# iostm32f105xx register map
Registers are 32-bit, access not given, no defined reset value unless marked. A register's access mark holds for its fields unless they carry their own. Addresses are absolute; registers are grouped by the start of their names; [hi:lo] are bit positions.

## SPI1
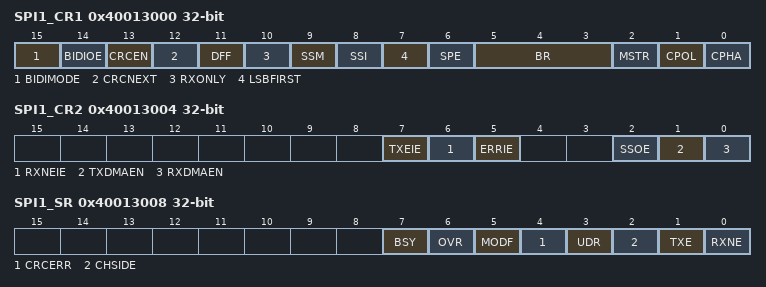
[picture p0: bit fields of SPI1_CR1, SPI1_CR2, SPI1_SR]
0x40013000 SPI1_CR1
  [15] BIDIMODE, [14] BIDIOE, [13] CRCEN, [12] CRCNEXT, [11] DFF, [10] RXONLY, [9] SSM, [8] SSI, [7] LSBFIRST, [6] SPE, [5:3] BR, [2] MSTR, [1] CPOL, [0] CPHA
0x40013004 SPI1_CR2
  [7] TXEIE, [6] RXNEIE, [5] ERRIE, [2] SSOE, [1] TXDMAEN, [0] RXDMAEN
0x40013008 SPI1_SR
  [7] BSY, [6] OVR, [5] MODF, [4] CRCERR, [3] UDR, [2] CHSIDE, [1] TXE, [0] RXNE
0x4001300C SPI1_DR
  [15:0] DR
0x40013010 SPI1_CRCPR
  [15:0] CRCPOLY
0x40013014 SPI1_RXCRCR
  [15:0] RxCRC
0x40013018 SPI1_TXCRCR
  [15:0] TxCRC

## SPI2
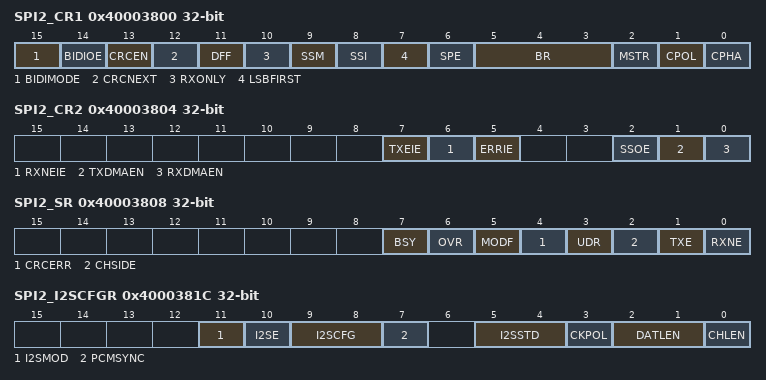
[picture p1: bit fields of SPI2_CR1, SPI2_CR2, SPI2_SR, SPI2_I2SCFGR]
0x40003800 SPI2_CR1
  [15] BIDIMODE, [14] BIDIOE, [13] CRCEN, [12] CRCNEXT, [11] DFF, [10] RXONLY, [9] SSM, [8] SSI, [7] LSBFIRST, [6] SPE, [5:3] BR, [2] MSTR, [1] CPOL, [0] CPHA
0x40003804 SPI2_CR2
  [7] TXEIE, [6] RXNEIE, [5] ERRIE, [2] SSOE, [1] TXDMAEN, [0] RXDMAEN
0x40003808 SPI2_SR
  [7] BSY, [6] OVR, [5] MODF, [4] CRCERR, [3] UDR, [2] CHSIDE, [1] TXE, [0] RXNE
0x4000380C SPI2_DR
  [15:0] DR
0x40003810 SPI2_CRCPR
  [15:0] CRCPOLY
0x40003814 SPI2_RXCRCR
  [15:0] RxCRC
0x40003818 SPI2_TXCRCR
  [15:0] TxCRC
0x4000381C SPI2_I2SCFGR
  [11] I2SMOD, [10] I2SE, [9:8] I2SCFG, [7] PCMSYNC, [5:4] I2SSTD, [3] CKPOL, [2:1] DATLEN, [0] CHLEN
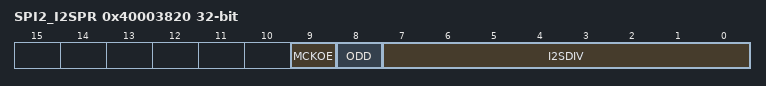
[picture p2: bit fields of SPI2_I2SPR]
0x40003820 SPI2_I2SPR
  [9] MCKOE, [8] ODD, [7:0] I2SDIV

## SPI3
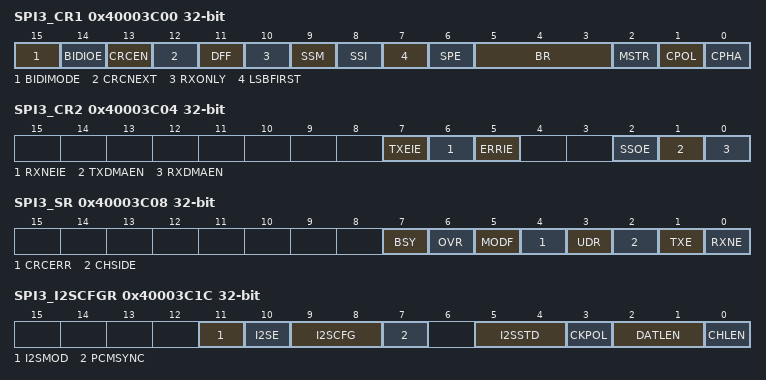
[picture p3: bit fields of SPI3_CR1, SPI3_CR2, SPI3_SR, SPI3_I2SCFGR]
0x40003C00 SPI3_CR1
  [15] BIDIMODE, [14] BIDIOE, [13] CRCEN, [12] CRCNEXT, [11] DFF, [10] RXONLY, [9] SSM, [8] SSI, [7] LSBFIRST, [6] SPE, [5:3] BR, [2] MSTR, [1] CPOL, [0] CPHA
0x40003C04 SPI3_CR2
  [7] TXEIE, [6] RXNEIE, [5] ERRIE, [2] SSOE, [1] TXDMAEN, [0] RXDMAEN
0x40003C08 SPI3_SR
  [7] BSY, [6] OVR, [5] MODF, [4] CRCERR, [3] UDR, [2] CHSIDE, [1] TXE, [0] RXNE
0x40003C0C SPI3_DR
  [15:0] DR
0x40003C10 SPI3_CRCPR
  [15:0] CRCPOLY
0x40003C14 SPI3_RXCRCR
  [15:0] RxCRC
0x40003C18 SPI3_TXCRCR
  [15:0] TxCRC
0x40003C1C SPI3_I2SCFGR
  [11] I2SMOD, [10] I2SE, [9:8] I2SCFG, [7] PCMSYNC, [5:4] I2SSTD, [3] CKPOL, [2:1] DATLEN, [0] CHLEN
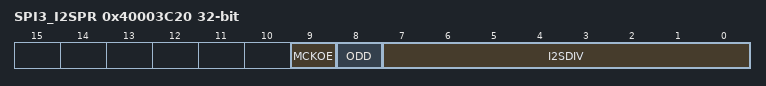
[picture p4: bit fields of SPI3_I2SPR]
0x40003C20 SPI3_I2SPR
  [9] MCKOE, [8] ODD, [7:0] I2SDIV

## USART1
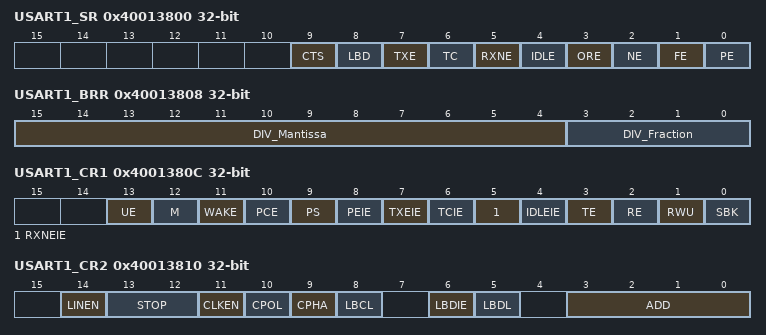
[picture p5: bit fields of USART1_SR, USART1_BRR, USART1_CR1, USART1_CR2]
0x40013800 USART1_SR
  [9] CTS, [8] LBD, [7] TXE, [6] TC, [5] RXNE, [4] IDLE, [3] ORE, [2] NE, [1] FE, [0] PE
0x40013804 USART1_DR
  [8:0] DR
0x40013808 USART1_BRR
  [15:4] DIV_Mantissa, [3:0] DIV_Fraction
0x4001380C USART1_CR1
  [13] UE, [12] M, [11] WAKE, [10] PCE, [9] PS, [8] PEIE, [7] TXEIE, [6] TCIE, [5] RXNEIE, [4] IDLEIE, [3] TE, [2] RE, [1] RWU, [0] SBK
0x40013810 USART1_CR2
  [14] LINEN, [13:12] STOP, [11] CLKEN, [10] CPOL, [9] CPHA, [8] LBCL, [6] LBDIE, [5] LBDL, [3:0] ADD
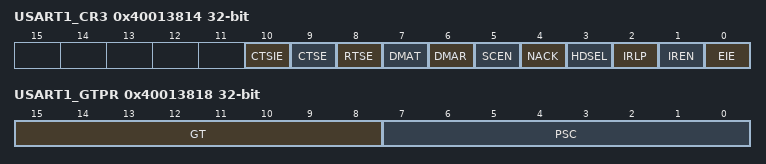
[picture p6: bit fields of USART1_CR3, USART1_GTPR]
0x40013814 USART1_CR3
  [10] CTSIE, [9] CTSE, [8] RTSE, [7] DMAT, [6] DMAR, [5] SCEN, [4] NACK, [3] HDSEL, [2] IRLP, [1] IREN, [0] EIE
0x40013818 USART1_GTPR
  [15:8] GT, [7:0] PSC

## USART2
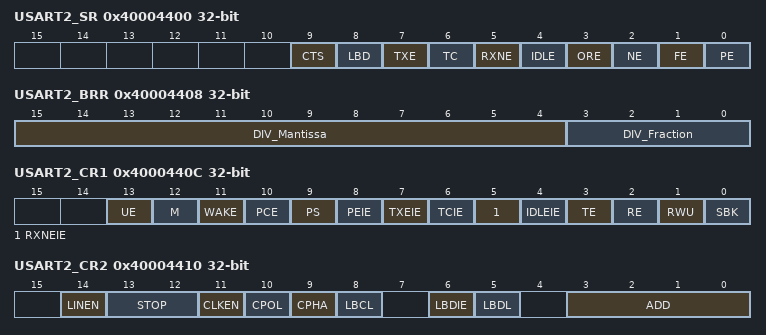
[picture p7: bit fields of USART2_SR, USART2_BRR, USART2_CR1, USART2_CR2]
0x40004400 USART2_SR
  [9] CTS, [8] LBD, [7] TXE, [6] TC, [5] RXNE, [4] IDLE, [3] ORE, [2] NE, [1] FE, [0] PE
0x40004404 USART2_DR
  [8:0] DR
0x40004408 USART2_BRR
  [15:4] DIV_Mantissa, [3:0] DIV_Fraction
0x4000440C USART2_CR1
  [13] UE, [12] M, [11] WAKE, [10] PCE, [9] PS, [8] PEIE, [7] TXEIE, [6] TCIE, [5] RXNEIE, [4] IDLEIE, [3] TE, [2] RE, [1] RWU, [0] SBK
0x40004410 USART2_CR2
  [14] LINEN, [13:12] STOP, [11] CLKEN, [10] CPOL, [9] CPHA, [8] LBCL, [6] LBDIE, [5] LBDL, [3:0] ADD
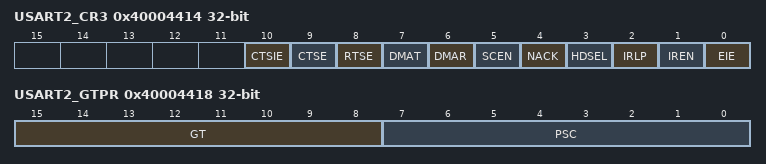
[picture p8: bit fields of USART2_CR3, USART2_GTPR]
0x40004414 USART2_CR3
  [10] CTSIE, [9] CTSE, [8] RTSE, [7] DMAT, [6] DMAR, [5] SCEN, [4] NACK, [3] HDSEL, [2] IRLP, [1] IREN, [0] EIE
0x40004418 USART2_GTPR
  [15:8] GT, [7:0] PSC

## USART3
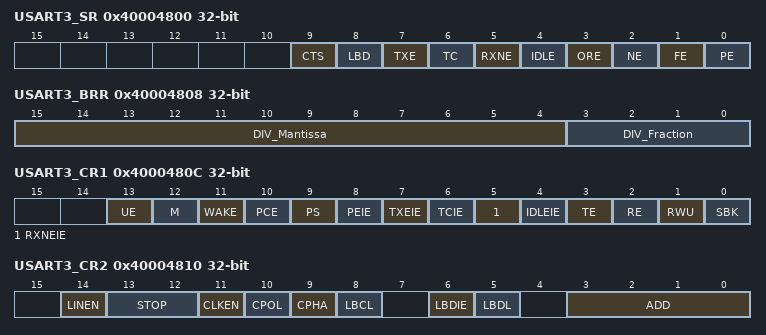
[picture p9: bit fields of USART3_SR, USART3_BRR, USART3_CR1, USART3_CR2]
0x40004800 USART3_SR
  [9] CTS, [8] LBD, [7] TXE, [6] TC, [5] RXNE, [4] IDLE, [3] ORE, [2] NE, [1] FE, [0] PE
0x40004804 USART3_DR
  [8:0] DR
0x40004808 USART3_BRR
  [15:4] DIV_Mantissa, [3:0] DIV_Fraction
0x4000480C USART3_CR1
  [13] UE, [12] M, [11] WAKE, [10] PCE, [9] PS, [8] PEIE, [7] TXEIE, [6] TCIE, [5] RXNEIE, [4] IDLEIE, [3] TE, [2] RE, [1] RWU, [0] SBK
0x40004810 USART3_CR2
  [14] LINEN, [13:12] STOP, [11] CLKEN, [10] CPOL, [9] CPHA, [8] LBCL, [6] LBDIE, [5] LBDL, [3:0] ADD
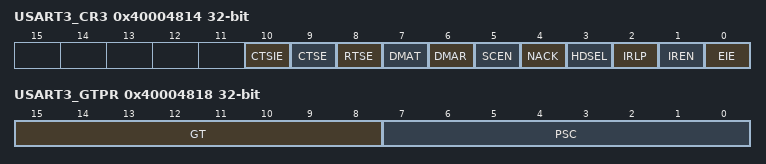
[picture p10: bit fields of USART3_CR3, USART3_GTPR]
0x40004814 USART3_CR3
  [10] CTSIE, [9] CTSE, [8] RTSE, [7] DMAT, [6] DMAR, [5] SCEN, [4] NACK, [3] HDSEL, [2] IRLP, [1] IREN, [0] EIE
0x40004818 USART3_GTPR
  [15:8] GT, [7:0] PSC
